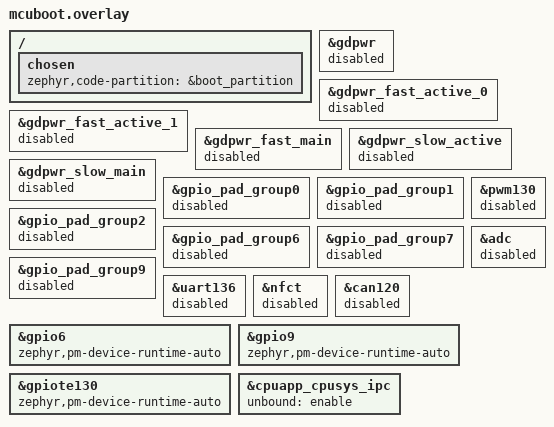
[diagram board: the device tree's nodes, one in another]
/*
 * Copyright (c) 2025 Nordic Semiconductor ASA
 *
 * SPDX-License-Identifier: Apache-2.0
 */

&gdpwr {
	status = "disabled";
};

&gdpwr_fast_active_0 {
	status = "disabled";
};

&gdpwr_fast_active_1 {
	status = "disabled";
};

&gdpwr_fast_main {
	status = "disabled";
};

&gdpwr_slow_active {
	status = "disabled";
};

&gdpwr_slow_main {
	status = "disabled";
};

&gpio_pad_group0 {
	status = "disabled";
};

&gpio_pad_group1 {
	status = "disabled";
};

&gpio_pad_group2 {
	status = "disabled";
};

&gpio_pad_group6 {
	status = "disabled";
};

&gpio_pad_group7 {
	status = "disabled";
};

&gpio_pad_group9 {
	status = "disabled";
};

/*
 * Copy from app.overlay as the board overlay take precedence
 * over app overlay.
 */

/ {
	chosen {
		zephyr,code-partition = &boot_partition;
	};
};

&uart136 {
    status = "disabled";
};

&pwm130 {
    status = "disabled";
};

&adc {
    status = "disabled";
};

&nfct {
    status = "disabled";
};

&can120 {
    status = "disabled";
};

&gpio6 {  
  zephyr,pm-device-runtime-auto;
}; 

&gpio9 {  
  zephyr,pm-device-runtime-auto;
}; 

&gpiote130 {
    zephyr,pm-device-runtime-auto;
};

/* From https://github.com/nrfconnect/sdk-zephyr/pull/3212 */

&cpuapp_cpusys_ipc {
	unbound = "enable";
};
